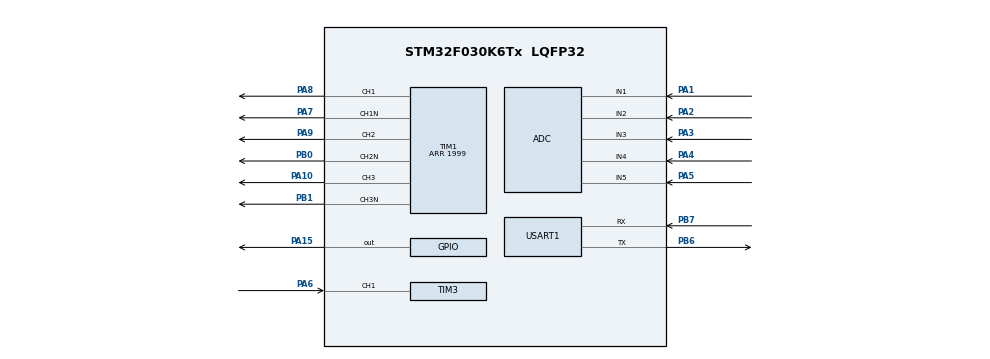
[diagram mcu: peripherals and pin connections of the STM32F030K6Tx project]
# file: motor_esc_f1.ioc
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ADC.ContinuousConvMode=ENABLE
ADC.DMAContinuousRequests=ENABLE
ADC.EOCSelection=ADC_EOC_SEQ_CONV
Dma.ADC.1.Direction=DMA_PERIPH_TO_MEMORY
Dma.ADC.1.Instance=DMA1_Channel1
Dma.ADC.1.MemDataAlignment=DMA_MDATAALIGN_HALFWORD
Dma.ADC.1.MemInc=DMA_MINC_ENABLE
Dma.ADC.1.Mode=DMA_NORMAL
Dma.ADC.1.PeriphDataAlignment=DMA_PDATAALIGN_HALFWORD
Dma.ADC.1.PeriphInc=DMA_PINC_DISABLE
Dma.ADC.1.Priority=DMA_PRIORITY_LOW
Dma.Request0=TIM3_CH1/TRIG
Dma.Request1=ADC
Dma.Request2=TIM1_CH1
Dma.Request3=TIM1_CH2
Dma.Request4=TIM1_CH3/UP
Dma.TIM1_CH1.2.Direction=DMA_PERIPH_TO_MEMORY
Dma.TIM1_CH1.2.Instance=DMA1_Channel2
Dma.TIM1_CH1.2.MemDataAlignment=DMA_MDATAALIGN_HALFWORD
Dma.TIM1_CH1.2.MemInc=DMA_MINC_ENABLE
Dma.TIM1_CH1.2.Mode=DMA_NORMAL
Dma.TIM1_CH1.2.PeriphDataAlignment=DMA_PDATAALIGN_HALFWORD
Dma.TIM1_CH1.2.PeriphInc=DMA_PINC_DISABLE
Dma.TIM1_CH1.2.Priority=DMA_PRIORITY_LOW
Dma.TIM1_CH2.3.Direction=DMA_PERIPH_TO_MEMORY
Dma.TIM1_CH2.3.Instance=DMA1_Channel3
Dma.TIM1_CH2.3.MemDataAlignment=DMA_MDATAALIGN_HALFWORD
Dma.TIM1_CH2.3.MemInc=DMA_MINC_ENABLE
Dma.TIM1_CH2.3.Mode=DMA_NORMAL
Dma.TIM1_CH2.3.PeriphDataAlignment=DMA_PDATAALIGN_HALFWORD
Dma.TIM1_CH2.3.PeriphInc=DMA_PINC_DISABLE
Dma.TIM1_CH2.3.Priority=DMA_PRIORITY_LOW
Dma.TIM1_CH3/UP.4.Direction=DMA_PERIPH_TO_MEMORY
Dma.TIM1_CH3/UP.4.Instance=DMA1_Channel5
Dma.TIM1_CH3/UP.4.MemDataAlignment=DMA_MDATAALIGN_HALFWORD
Dma.TIM1_CH3/UP.4.MemInc=DMA_MINC_ENABLE
Dma.TIM1_CH3/UP.4.Mode=DMA_NORMAL
Dma.TIM1_CH3/UP.4.PeriphDataAlignment=DMA_PDATAALIGN_HALFWORD
Dma.TIM1_CH3/UP.4.PeriphInc=DMA_PINC_DISABLE
Dma.TIM1_CH3/UP.4.Priority=DMA_PRIORITY_LOW
Dma.TIM3_CH1/TRIG.0.Direction=DMA_PERIPH_TO_MEMORY
Dma.TIM3_CH1/TRIG.0.Instance=DMA1_Channel4
Dma.TIM3_CH1/TRIG.0.MemDataAlignment=DMA_MDATAALIGN_HALFWORD
Dma.TIM3_CH1/TRIG.0.MemInc=DMA_MINC_ENABLE
Dma.TIM3_CH1/TRIG.0.Mode=DMA_NORMAL
Dma.TIM3_CH1/TRIG.0.PeriphDataAlignment=DMA_PDATAALIGN_HALFWORD
Dma.TIM3_CH1/TRIG.0.PeriphInc=DMA_PINC_DISABLE
Dma.TIM3_CH1/TRIG.0.Priority=DMA_PRIORITY_LOW
Mcu.Family=STM32F0
Mcu.Name=STM32F030K6Tx
Mcu.Package=LQFP32
NVIC.DMA1_Channel1_IRQn=true\:0\:0\:false\:false\:true\:false\:true\:true
NVIC.DMA1_Channel2_3_IRQn=true\:0\:0\:false\:false\:true\:false\:true\:true
NVIC.DMA1_Channel4_5_IRQn=true\:0\:0\:false\:false\:true\:false\:true\:true
NVIC.TIM14_IRQn=true\:0\:0\:false\:false\:true\:true\:true\:true
NVIC.TIM1_BRK_UP_TRG_COM_IRQn=true\:0\:0\:false\:false\:true\:true\:true\:true
NVIC.TIM3_IRQn=true\:0\:0\:false\:false\:true\:true\:true\:true
PA1.Mode=IN1
PA1.Signal=ADC_IN1
PA10.Signal=S_TIM1_CH3
PA13.Mode=Serial_Wire
PA13.Signal=SYS_SWDIO
PA14.Mode=Serial_Wire
PA14.Signal=SYS_SWCLK
PA15.Signal=GPIO_Output
PA2.Mode=IN2
PA2.Signal=ADC_IN2
PA3.Mode=IN3
PA3.Signal=ADC_IN3
PA4.Mode=IN4
PA4.Signal=ADC_IN4
PA5.Mode=IN5
PA5.Signal=ADC_IN5
PA6.Signal=S_TIM3_CH1
PA7.Mode=PWM Generation1 CH1 CH1N
PA7.Signal=TIM1_CH1N
PA8.Signal=S_TIM1_CH1
PA9.Signal=S_TIM1_CH2
PB0.Mode=PWM Generation2 CH2 CH2N
PB0.Signal=TIM1_CH2N
PB1.Mode=PWM Generation3 CH3 CH3N
PB1.Signal=TIM1_CH3N
PB6.Mode=Asynchronous
PB6.Signal=USART1_TX
PB7.Mode=Asynchronous
PB7.Signal=USART1_RX
ProjectManager.HeapSize=0x200
ProjectManager.StackSize=0x400
ProjectManager.TargetToolchain=STM32CubeIDE
RCC.AHBFreq_Value=48000000
RCC.APB1Freq_Value=48000000
RCC.APB1TimFreq_Value=48000000
RCC.HCLKFreq_Value=48000000
RCC.PLLMUL=RCC_PLL_MUL12
RCC.SYSCLKFreq_VALUE=48000000
RCC.SYSCLKSource=RCC_SYSCLKSOURCE_PLLCLK
SH.S_TIM1_CH1.0=TIM1_CH1,PWM Generation1 CH1 CH1N
SH.S_TIM1_CH2.0=TIM1_CH2,PWM Generation2 CH2 CH2N
SH.S_TIM1_CH3.0=TIM1_CH3,PWM Generation3 CH3 CH3N
SH.S_TIM3_CH1.0=TIM3_CH1,Input_Capture1_from_TI1
TIM1.Channel-PWM\ Generation1\ CH1\ CH1N=TIM_CHANNEL_1
TIM1.Channel-PWM\ Generation2\ CH2\ CH2N=TIM_CHANNEL_2
TIM1.Channel-PWM\ Generation3\ CH3\ CH3N=TIM_CHANNEL_3
TIM1.DeadTime=45
TIM1.OCIdleState_1=TIM_OCIDLESTATE_SET
TIM1.OCIdleState_2=TIM_OCIDLESTATE_SET
TIM1.OCIdleState_3=TIM_OCIDLESTATE_SET
TIM1.OCNIdleState_1=TIM_OCNIDLESTATE_RESET
TIM1.Period=1999
TIM1.Pulse-PWM\ Generation1\ CH1\ CH1N=1000
TIM1.Pulse-PWM\ Generation3\ CH3\ CH3N=1000
TIM1.TIM_MasterOutputTrigger=TIM_TRGO_ENABLE
TIM14.AutoReloadPreload=TIM_AUTORELOAD_PRELOAD_ENABLE
TIM14.Channel=TIM_CHANNEL_1
TIM14.Period=16000
TIM14.Prescaler=10
TIM16.AutoReloadPreload=TIM_AUTORELOAD_PRELOAD_ENABLE
TIM16.Prescaler=479
TIM17.AutoReloadPreload=TIM_AUTORELOAD_PRELOAD_ENABLE
TIM3.Channel-Input_Capture1_from_TI1=TIM_CHANNEL_1
TIM3.Prescaler=99
USART1.VirtualMode-Asynchronous=VM_ASYNC
VP_ADC_TempSens_Input.Mode=IN-TempSens
VP_TIM14_VS_ClockSourceINT.Mode=Enable_Timer
VP_TIM14_VS_no_output1.Mode=Output Compare1 No Output
VP_TIM16_VS_ClockSourceINT.Mode=Enable_Timer
VP_TIM17_VS_ClockSourceINT.Mode=Enable_Timer
VP_TIM1_VS_ClockSourceINT.Mode=Internal
board=custom

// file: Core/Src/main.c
/* USER CODE BEGIN Header */
/**
  ******************************************************************************
  * @file           : main.c
  * @brief          : Main program body
  ******************************************************************************
  * @attention
  *
  * Copyright (c) 2022 STMicroelectronics.
  * All rights reserved.
  *
  * This software is licensed under terms that can be found in the LICENSE file
  * in the root directory of this software component.
  * If no LICENSE file comes with this software, it is provided AS-IS.
  *
  ******************************************************************************
  */
/* USER CODE END Header */
#include "main.h"

void SystemClock_Config(void);
static void MX_GPIO_Init(void);
static void MX_DMA_Init(void);
static void MX_TIM1_Init(void);
static void MX_ADC_Init(void);
static void MX_TIM3_Init(void);
static void MX_TIM14_Init(void);
static void MX_USART1_UART_Init(void);
static void MX_TIM16_Init(void);
static void MX_TIM17_Init(void);

int main(void)
{

  /* MCU Configuration--------------------------------------------------------*/

  /* Reset of all peripherals, Initializes the Flash interface and the Systick. */
  LL_APB1_GRP2_EnableClock(LL_APB1_GRP2_PERIPH_SYSCFG);
  LL_APB1_GRP1_EnableClock(LL_APB1_GRP1_PERIPH_PWR);

  /* SysTick_IRQn interrupt configuration */
  NVIC_SetPriority(SysTick_IRQn, 3);

  /* Configure the system clock */
  SystemClock_Config();

  /* Initialize all configured peripherals */
  MX_GPIO_Init();
  MX_DMA_Init();
  MX_TIM1_Init();
  MX_ADC_Init();
  MX_TIM3_Init();
  MX_TIM14_Init();
  MX_USART1_UART_Init();
  MX_TIM16_Init();
  MX_TIM17_Init();
  /* USER CODE BEGIN 2 */
  LL_GPIO_SetOutputPin(GPIOA, LL_GPIO_PIN_15);
  /* USER CODE END 2 */

  /* Infinite loop */
  while (1)
  {

  }
}

void SystemClock_Config(void)
{
  LL_FLASH_SetLatency(LL_FLASH_LATENCY_1);
  while(LL_FLASH_GetLatency() != LL_FLASH_LATENCY_1)
  {
  }
  LL_RCC_HSI_Enable();

   /* Wait till HSI is ready */
  while(LL_RCC_HSI_IsReady() != 1)
  {

  }
  LL_RCC_HSI_SetCalibTrimming(16);
  LL_RCC_HSI14_Enable();

   /* Wait till HSI14 is ready */
  while(LL_RCC_HSI14_IsReady() != 1)
  {

  }
  LL_RCC_HSI14_SetCalibTrimming(16);
  LL_RCC_PLL_ConfigDomain_SYS(LL_RCC_PLLSOURCE_HSI_DIV_2, LL_RCC_PLL_MUL_12);
  LL_RCC_PLL_Enable();

   /* Wait till PLL is ready */
  while(LL_RCC_PLL_IsReady() != 1)
  {

  }
  LL_RCC_SetAHBPrescaler(LL_RCC_SYSCLK_DIV_1);
  LL_RCC_SetAPB1Prescaler(LL_RCC_APB1_DIV_1);
  LL_RCC_SetSysClkSource(LL_RCC_SYS_CLKSOURCE_PLL);

   /* Wait till System clock is ready */
  while(LL_RCC_GetSysClkSource() != LL_RCC_SYS_CLKSOURCE_STATUS_PLL)
  {

  }
  LL_Init1msTick(48000000);
  LL_SetSystemCoreClock(48000000);
  LL_RCC_HSI14_EnableADCControl();
  LL_RCC_SetUSARTClockSource(LL_RCC_USART1_CLKSOURCE_PCLK1);
}

static void MX_ADC_Init(void)
{

  LL_ADC_InitTypeDef ADC_InitStruct = {0};
  LL_ADC_REG_InitTypeDef ADC_REG_InitStruct = {0};

  LL_GPIO_InitTypeDef GPIO_InitStruct = {0};

  /* Peripheral clock enable */
  LL_APB1_GRP2_EnableClock(LL_APB1_GRP2_PERIPH_ADC1);

  LL_AHB1_GRP1_EnableClock(LL_AHB1_GRP1_PERIPH_GPIOA);
  /**ADC GPIO Configuration
  PA1   ------> ADC_IN1
  PA2   ------> ADC_IN2
  PA3   ------> ADC_IN3
  PA4   ------> ADC_IN4
  PA5   ------> ADC_IN5
  */
  GPIO_InitStruct.Pin = LL_GPIO_PIN_1;
  GPIO_InitStruct.Mode = LL_GPIO_MODE_ANALOG;
  GPIO_InitStruct.Pull = LL_GPIO_PULL_NO;
  LL_GPIO_Init(GPIOA, &GPIO_InitStruct);

  GPIO_InitStruct.Pin = LL_GPIO_PIN_2;
  GPIO_InitStruct.Mode = LL_GPIO_MODE_ANALOG;
  GPIO_InitStruct.Pull = LL_GPIO_PULL_NO;
  LL_GPIO_Init(GPIOA, &GPIO_InitStruct);

  GPIO_InitStruct.Pin = LL_GPIO_PIN_3;
  GPIO_InitStruct.Mode = LL_GPIO_MODE_ANALOG;
  GPIO_InitStruct.Pull = LL_GPIO_PULL_NO;
  LL_GPIO_Init(GPIOA, &GPIO_InitStruct);

  GPIO_InitStruct.Pin = LL_GPIO_PIN_4;
  GPIO_InitStruct.Mode = LL_GPIO_MODE_ANALOG;
  GPIO_InitStruct.Pull = LL_GPIO_PULL_NO;
  LL_GPIO_Init(GPIOA, &GPIO_InitStruct);

  GPIO_InitStruct.Pin = LL_GPIO_PIN_5;
  GPIO_InitStruct.Mode = LL_GPIO_MODE_ANALOG;
  GPIO_InitStruct.Pull = LL_GPIO_PULL_NO;
  LL_GPIO_Init(GPIOA, &GPIO_InitStruct);

  /* ADC DMA Init */

  /* ADC Init */
  LL_DMA_SetDataTransferDirection(DMA1, LL_DMA_CHANNEL_1, LL_DMA_DIRECTION_PERIPH_TO_MEMORY);

  LL_DMA_SetChannelPriorityLevel(DMA1, LL_DMA_CHANNEL_1, LL_DMA_PRIORITY_LOW);

  LL_DMA_SetMode(DMA1, LL_DMA_CHANNEL_1, LL_DMA_MODE_NORMAL);

  LL_DMA_SetPeriphIncMode(DMA1, LL_DMA_CHANNEL_1, LL_DMA_PERIPH_NOINCREMENT);

  LL_DMA_SetMemoryIncMode(DMA1, LL_DMA_CHANNEL_1, LL_DMA_MEMORY_INCREMENT);

  LL_DMA_SetPeriphSize(DMA1, LL_DMA_CHANNEL_1, LL_DMA_PDATAALIGN_HALFWORD);

  LL_DMA_SetMemorySize(DMA1, LL_DMA_CHANNEL_1, LL_DMA_MDATAALIGN_HALFWORD);

  /** Configure Regular Channel
  */
  LL_ADC_REG_SetSequencerChAdd(ADC1, LL_ADC_CHANNEL_1);

  /** Configure Regular Channel
  */
  LL_ADC_REG_SetSequencerChAdd(ADC1, LL_ADC_CHANNEL_2);

  /** Configure Regular Channel
  */
  LL_ADC_REG_SetSequencerChAdd(ADC1, LL_ADC_CHANNEL_3);

  /** Configure Regular Channel
  */
  LL_ADC_REG_SetSequencerChAdd(ADC1, LL_ADC_CHANNEL_4);

  /** Configure Regular Channel
  */
  LL_ADC_REG_SetSequencerChAdd(ADC1, LL_ADC_CHANNEL_5);

  /** Configure Regular Channel
  */
  LL_ADC_REG_SetSequencerChAdd(ADC1, LL_ADC_CHANNEL_TEMPSENSOR);

  /** Configure Internal Channel
  */
  LL_ADC_SetCommonPathInternalCh(__LL_ADC_COMMON_INSTANCE(ADC1), LL_ADC_PATH_INTERNAL_TEMPSENSOR);

  /** Configure the global features of the ADC (Clock, Resolution, Data Alignment and number of conversion)
  */
  ADC_InitStruct.Clock = LL_ADC_CLOCK_ASYNC;
  ADC_InitStruct.Resolution = LL_ADC_RESOLUTION_12B;
  ADC_InitStruct.DataAlignment = LL_ADC_DATA_ALIGN_RIGHT;
  ADC_InitStruct.LowPowerMode = LL_ADC_LP_MODE_NONE;
  LL_ADC_Init(ADC1, &ADC_InitStruct);
  ADC_REG_InitStruct.TriggerSource = LL_ADC_REG_TRIG_SOFTWARE;
  ADC_REG_InitStruct.SequencerDiscont = LL_ADC_REG_SEQ_DISCONT_DISABLE;
  ADC_REG_InitStruct.ContinuousMode = LL_ADC_REG_CONV_CONTINUOUS;
  ADC_REG_InitStruct.DMATransfer = LL_ADC_REG_DMA_TRANSFER_UNLIMITED;
  ADC_REG_InitStruct.Overrun = LL_ADC_REG_OVR_DATA_PRESERVED;
  LL_ADC_REG_Init(ADC1, &ADC_REG_InitStruct);
  LL_ADC_REG_SetSequencerScanDirection(ADC1, LL_ADC_REG_SEQ_SCAN_DIR_FORWARD);
  LL_ADC_SetSamplingTimeCommonChannels(ADC1, LL_ADC_SAMPLINGTIME_1CYCLE_5);

}

static void MX_TIM1_Init(void)
{

  LL_TIM_InitTypeDef TIM_InitStruct = {0};
  LL_TIM_OC_InitTypeDef TIM_OC_InitStruct = {0};
  LL_TIM_BDTR_InitTypeDef TIM_BDTRInitStruct = {0};

  LL_GPIO_InitTypeDef GPIO_InitStruct = {0};

  /* Peripheral clock enable */
  LL_APB1_GRP2_EnableClock(LL_APB1_GRP2_PERIPH_TIM1);

  /* TIM1 DMA Init */

  /* TIM1_CH1 Init */
  LL_DMA_SetDataTransferDirection(DMA1, LL_DMA_CHANNEL_2, LL_DMA_DIRECTION_PERIPH_TO_MEMORY);

  LL_DMA_SetChannelPriorityLevel(DMA1, LL_DMA_CHANNEL_2, LL_DMA_PRIORITY_LOW);

  LL_DMA_SetMode(DMA1, LL_DMA_CHANNEL_2, LL_DMA_MODE_NORMAL);

  LL_DMA_SetPeriphIncMode(DMA1, LL_DMA_CHANNEL_2, LL_DMA_PERIPH_NOINCREMENT);

  LL_DMA_SetMemoryIncMode(DMA1, LL_DMA_CHANNEL_2, LL_DMA_MEMORY_INCREMENT);

  LL_DMA_SetPeriphSize(DMA1, LL_DMA_CHANNEL_2, LL_DMA_PDATAALIGN_HALFWORD);

  LL_DMA_SetMemorySize(DMA1, LL_DMA_CHANNEL_2, LL_DMA_MDATAALIGN_HALFWORD);

  /* TIM1_CH2 Init */
  LL_DMA_SetDataTransferDirection(DMA1, LL_DMA_CHANNEL_3, LL_DMA_DIRECTION_PERIPH_TO_MEMORY);

  LL_DMA_SetChannelPriorityLevel(DMA1, LL_DMA_CHANNEL_3, LL_DMA_PRIORITY_LOW);

  LL_DMA_SetMode(DMA1, LL_DMA_CHANNEL_3, LL_DMA_MODE_NORMAL);

  LL_DMA_SetPeriphIncMode(DMA1, LL_DMA_CHANNEL_3, LL_DMA_PERIPH_NOINCREMENT);

  LL_DMA_SetMemoryIncMode(DMA1, LL_DMA_CHANNEL_3, LL_DMA_MEMORY_INCREMENT);

  LL_DMA_SetPeriphSize(DMA1, LL_DMA_CHANNEL_3, LL_DMA_PDATAALIGN_HALFWORD);

  LL_DMA_SetMemorySize(DMA1, LL_DMA_CHANNEL_3, LL_DMA_MDATAALIGN_HALFWORD);

  /* TIM1_CH3_UP Init */
  LL_DMA_SetDataTransferDirection(DMA1, LL_DMA_CHANNEL_5, LL_DMA_DIRECTION_PERIPH_TO_MEMORY);

  LL_DMA_SetChannelPriorityLevel(DMA1, LL_DMA_CHANNEL_5, LL_DMA_PRIORITY_LOW);

  LL_DMA_SetMode(DMA1, LL_DMA_CHANNEL_5, LL_DMA_MODE_NORMAL);

  LL_DMA_SetPeriphIncMode(DMA1, LL_DMA_CHANNEL_5, LL_DMA_PERIPH_NOINCREMENT);

  LL_DMA_SetMemoryIncMode(DMA1, LL_DMA_CHANNEL_5, LL_DMA_MEMORY_INCREMENT);

  LL_DMA_SetPeriphSize(DMA1, LL_DMA_CHANNEL_5, LL_DMA_PDATAALIGN_HALFWORD);

  LL_DMA_SetMemorySize(DMA1, LL_DMA_CHANNEL_5, LL_DMA_MDATAALIGN_HALFWORD);

  /* TIM1 interrupt Init */
  NVIC_SetPriority(TIM1_BRK_UP_TRG_COM_IRQn, 0);
  NVIC_EnableIRQ(TIM1_BRK_UP_TRG_COM_IRQn);

  TIM_InitStruct.Prescaler = 0;
  TIM_InitStruct.CounterMode = LL_TIM_COUNTERMODE_UP;
  TIM_InitStruct.Autoreload = 1999;
  TIM_InitStruct.ClockDivision = LL_TIM_CLOCKDIVISION_DIV1;
  TIM_InitStruct.RepetitionCounter = 0;
  LL_TIM_Init(TIM1, &TIM_InitStruct);
  LL_TIM_DisableARRPreload(TIM1);
  LL_TIM_SetClockSource(TIM1, LL_TIM_CLOCKSOURCE_INTERNAL);
  LL_TIM_OC_EnablePreload(TIM1, LL_TIM_CHANNEL_CH1);
  TIM_OC_InitStruct.OCMode = LL_TIM_OCMODE_PWM1;
  TIM_OC_InitStruct.OCState = LL_TIM_OCSTATE_DISABLE;
  TIM_OC_InitStruct.OCNState = LL_TIM_OCSTATE_DISABLE;
  TIM_OC_InitStruct.CompareValue = 1000;
  TIM_OC_InitStruct.OCPolarity = LL_TIM_OCPOLARITY_HIGH;
  TIM_OC_InitStruct.OCNPolarity = LL_TIM_OCPOLARITY_HIGH;
  TIM_OC_InitStruct.OCIdleState = LL_TIM_OCIDLESTATE_HIGH;
  TIM_OC_InitStruct.OCNIdleState = LL_TIM_OCIDLESTATE_LOW;
  LL_TIM_OC_Init(TIM1, LL_TIM_CHANNEL_CH1, &TIM_OC_InitStruct);
  LL_TIM_OC_DisableFast(TIM1, LL_TIM_CHANNEL_CH1);
  LL_TIM_OC_EnablePreload(TIM1, LL_TIM_CHANNEL_CH2);
  TIM_OC_InitStruct.CompareValue = 0;
  LL_TIM_OC_Init(TIM1, LL_TIM_CHANNEL_CH2, &TIM_OC_InitStruct);
  LL_TIM_OC_DisableFast(TIM1, LL_TIM_CHANNEL_CH2);
  LL_TIM_OC_EnablePreload(TIM1, LL_TIM_CHANNEL_CH3);
  TIM_OC_InitStruct.CompareValue = 1000;
  LL_TIM_OC_Init(TIM1, LL_TIM_CHANNEL_CH3, &TIM_OC_InitStruct);
  LL_TIM_OC_DisableFast(TIM1, LL_TIM_CHANNEL_CH3);
  LL_TIM_SetTriggerOutput(TIM1, LL_TIM_TRGO_ENABLE);
  LL_TIM_DisableMasterSlaveMode(TIM1);
  TIM_BDTRInitStruct.OSSRState = LL_TIM_OSSR_DISABLE;
  TIM_BDTRInitStruct.OSSIState = LL_TIM_OSSI_DISABLE;
  TIM_BDTRInitStruct.LockLevel = LL_TIM_LOCKLEVEL_OFF;
  TIM_BDTRInitStruct.DeadTime = 45;
  TIM_BDTRInitStruct.BreakState = LL_TIM_BREAK_DISABLE;
  TIM_BDTRInitStruct.BreakPolarity = LL_TIM_BREAK_POLARITY_HIGH;
  TIM_BDTRInitStruct.AutomaticOutput = LL_TIM_AUTOMATICOUTPUT_DISABLE;
  LL_TIM_BDTR_Init(TIM1, &TIM_BDTRInitStruct);
  LL_AHB1_GRP1_EnableClock(LL_AHB1_GRP1_PERIPH_GPIOA);
  LL_AHB1_GRP1_EnableClock(LL_AHB1_GRP1_PERIPH_GPIOB);
  /**TIM1 GPIO Configuration
  PA7   ------> TIM1_CH1N
  PB0   ------> TIM1_CH2N
  PB1   ------> TIM1_CH3N
  PA8   ------> TIM1_CH1
  PA9   ------> TIM1_CH2
  PA10   ------> TIM1_CH3
  */
  GPIO_InitStruct.Pin = LL_GPIO_PIN_7;
  GPIO_InitStruct.Mode = LL_GPIO_MODE_ALTERNATE;
  GPIO_InitStruct.Speed = LL_GPIO_SPEED_FREQ_LOW;
  GPIO_InitStruct.OutputType = LL_GPIO_OUTPUT_PUSHPULL;
  GPIO_InitStruct.Pull = LL_GPIO_PULL_NO;
  GPIO_InitStruct.Alternate = LL_GPIO_AF_2;
  LL_GPIO_Init(GPIOA, &GPIO_InitStruct);

  GPIO_InitStruct.Pin = LL_GPIO_PIN_0;
  GPIO_InitStruct.Mode = LL_GPIO_MODE_ALTERNATE;
  GPIO_InitStruct.Speed = LL_GPIO_SPEED_FREQ_LOW;
  GPIO_InitStruct.OutputType = LL_GPIO_OUTPUT_PUSHPULL;
  GPIO_InitStruct.Pull = LL_GPIO_PULL_NO;
  GPIO_InitStruct.Alternate = LL_GPIO_AF_2;
  LL_GPIO_Init(GPIOB, &GPIO_InitStruct);

  GPIO_InitStruct.Pin = LL_GPIO_PIN_1;
  GPIO_InitStruct.Mode = LL_GPIO_MODE_ALTERNATE;
  GPIO_InitStruct.Speed = LL_GPIO_SPEED_FREQ_LOW;
  GPIO_InitStruct.OutputType = LL_GPIO_OUTPUT_PUSHPULL;
  GPIO_InitStruct.Pull = LL_GPIO_PULL_NO;
  GPIO_InitStruct.Alternate = LL_GPIO_AF_2;
  LL_GPIO_Init(GPIOB, &GPIO_InitStruct);

  GPIO_InitStruct.Pin = LL_GPIO_PIN_8;
  GPIO_InitStruct.Mode = LL_GPIO_MODE_ALTERNATE;
  GPIO_InitStruct.Speed = LL_GPIO_SPEED_FREQ_LOW;
  GPIO_InitStruct.OutputType = LL_GPIO_OUTPUT_PUSHPULL;
  GPIO_InitStruct.Pull = LL_GPIO_PULL_NO;
  GPIO_InitStruct.Alternate = LL_GPIO_AF_2;
  LL_GPIO_Init(GPIOA, &GPIO_InitStruct);

  GPIO_InitStruct.Pin = LL_GPIO_PIN_9;
  GPIO_InitStruct.Mode = LL_GPIO_MODE_ALTERNATE;
  GPIO_InitStruct.Speed = LL_GPIO_SPEED_FREQ_LOW;
  GPIO_InitStruct.OutputType = LL_GPIO_OUTPUT_PUSHPULL;
  GPIO_InitStruct.Pull = LL_GPIO_PULL_NO;
  GPIO_InitStruct.Alternate = LL_GPIO_AF_2;
  LL_GPIO_Init(GPIOA, &GPIO_InitStruct);

  GPIO_InitStruct.Pin = LL_GPIO_PIN_10;
  GPIO_InitStruct.Mode = LL_GPIO_MODE_ALTERNATE;
  GPIO_InitStruct.Speed = LL_GPIO_SPEED_FREQ_LOW;
  GPIO_InitStruct.OutputType = LL_GPIO_OUTPUT_PUSHPULL;
  GPIO_InitStruct.Pull = LL_GPIO_PULL_NO;
  GPIO_InitStruct.Alternate = LL_GPIO_AF_2;
  LL_GPIO_Init(GPIOA, &GPIO_InitStruct);

}

static void MX_TIM3_Init(void)
{

  LL_TIM_InitTypeDef TIM_InitStruct = {0};

  LL_GPIO_InitTypeDef GPIO_InitStruct = {0};

  /* Peripheral clock enable */
  LL_APB1_GRP1_EnableClock(LL_APB1_GRP1_PERIPH_TIM3);

  LL_AHB1_GRP1_EnableClock(LL_AHB1_GRP1_PERIPH_GPIOA);
  /**TIM3 GPIO Configuration
  PA6   ------> TIM3_CH1
  */
  GPIO_InitStruct.Pin = LL_GPIO_PIN_6;
  GPIO_InitStruct.Mode = LL_GPIO_MODE_ALTERNATE;
  GPIO_InitStruct.Speed = LL_GPIO_SPEED_FREQ_LOW;
  GPIO_InitStruct.OutputType = LL_GPIO_OUTPUT_PUSHPULL;
  GPIO_InitStruct.Pull = LL_GPIO_PULL_NO;
  GPIO_InitStruct.Alternate = LL_GPIO_AF_1;
  LL_GPIO_Init(GPIOA, &GPIO_InitStruct);

  /* TIM3 DMA Init */

  /* TIM3_CH1_TRIG Init */
  LL_DMA_SetDataTransferDirection(DMA1, LL_DMA_CHANNEL_4, LL_DMA_DIRECTION_PERIPH_TO_MEMORY);

  LL_DMA_SetChannelPriorityLevel(DMA1, LL_DMA_CHANNEL_4, LL_DMA_PRIORITY_LOW);

  LL_DMA_SetMode(DMA1, LL_DMA_CHANNEL_4, LL_DMA_MODE_NORMAL);

  LL_DMA_SetPeriphIncMode(DMA1, LL_DMA_CHANNEL_4, LL_DMA_PERIPH_NOINCREMENT);

  LL_DMA_SetMemoryIncMode(DMA1, LL_DMA_CHANNEL_4, LL_DMA_MEMORY_INCREMENT);

  LL_DMA_SetPeriphSize(DMA1, LL_DMA_CHANNEL_4, LL_DMA_PDATAALIGN_HALFWORD);

  LL_DMA_SetMemorySize(DMA1, LL_DMA_CHANNEL_4, LL_DMA_MDATAALIGN_HALFWORD);

  /* TIM3 interrupt Init */
  NVIC_SetPriority(TIM3_IRQn, 0);
  NVIC_EnableIRQ(TIM3_IRQn);

  TIM_InitStruct.Prescaler = 99;
  TIM_InitStruct.CounterMode = LL_TIM_COUNTERMODE_UP;
  TIM_InitStruct.Autoreload = 65535;
  TIM_InitStruct.ClockDivision = LL_TIM_CLOCKDIVISION_DIV1;
  LL_TIM_Init(TIM3, &TIM_InitStruct);
  LL_TIM_DisableARRPreload(TIM3);
  LL_TIM_SetTriggerOutput(TIM3, LL_TIM_TRGO_RESET);
  LL_TIM_DisableMasterSlaveMode(TIM3);
  LL_TIM_IC_SetActiveInput(TIM3, LL_TIM_CHANNEL_CH1, LL_TIM_ACTIVEINPUT_DIRECTTI);
  LL_TIM_IC_SetPrescaler(TIM3, LL_TIM_CHANNEL_CH1, LL_TIM_ICPSC_DIV1);
  LL_TIM_IC_SetFilter(TIM3, LL_TIM_CHANNEL_CH1, LL_TIM_IC_FILTER_FDIV1);
  LL_TIM_IC_SetPolarity(TIM3, LL_TIM_CHANNEL_CH1, LL_TIM_IC_POLARITY_RISING);

}

static void MX_TIM14_Init(void)
{

  LL_TIM_InitTypeDef TIM_InitStruct = {0};
  LL_TIM_OC_InitTypeDef TIM_OC_InitStruct = {0};

  /* Peripheral clock enable */
  LL_APB1_GRP1_EnableClock(LL_APB1_GRP1_PERIPH_TIM14);

  /* TIM14 interrupt Init */
  NVIC_SetPriority(TIM14_IRQn, 0);
  NVIC_EnableIRQ(TIM14_IRQn);

  TIM_InitStruct.Prescaler = 10;
  TIM_InitStruct.CounterMode = LL_TIM_COUNTERMODE_UP;
  TIM_InitStruct.Autoreload = 16000;
  TIM_InitStruct.ClockDivision = LL_TIM_CLOCKDIVISION_DIV1;
  LL_TIM_Init(TIM14, &TIM_InitStruct);
  LL_TIM_EnableARRPreload(TIM14);
  TIM_OC_InitStruct.OCMode = LL_TIM_OCMODE_FROZEN;
  TIM_OC_InitStruct.OCState = LL_TIM_OCSTATE_DISABLE;
  TIM_OC_InitStruct.OCNState = LL_TIM_OCSTATE_DISABLE;
  TIM_OC_InitStruct.CompareValue = 0;
  TIM_OC_InitStruct.OCPolarity = LL_TIM_OCPOLARITY_HIGH;
  LL_TIM_OC_Init(TIM14, LL_TIM_CHANNEL_CH1, &TIM_OC_InitStruct);
  LL_TIM_OC_DisableFast(TIM14, LL_TIM_CHANNEL_CH1);

}

static void MX_TIM16_Init(void)
{

  LL_TIM_InitTypeDef TIM_InitStruct = {0};

  /* Peripheral clock enable */
  LL_APB1_GRP2_EnableClock(LL_APB1_GRP2_PERIPH_TIM16);

  TIM_InitStruct.Prescaler = 479;
  TIM_InitStruct.CounterMode = LL_TIM_COUNTERMODE_UP;
  TIM_InitStruct.Autoreload = 65535;
  TIM_InitStruct.ClockDivision = LL_TIM_CLOCKDIVISION_DIV1;
  TIM_InitStruct.RepetitionCounter = 0;
  LL_TIM_Init(TIM16, &TIM_InitStruct);
  LL_TIM_EnableARRPreload(TIM16);

}

static void MX_TIM17_Init(void)
{

  LL_TIM_InitTypeDef TIM_InitStruct = {0};

  /* Peripheral clock enable */
  LL_APB1_GRP2_EnableClock(LL_APB1_GRP2_PERIPH_TIM17);

  TIM_InitStruct.Prescaler = 0;
  TIM_InitStruct.CounterMode = LL_TIM_COUNTERMODE_UP;
  TIM_InitStruct.Autoreload = 65535;
  TIM_InitStruct.ClockDivision = LL_TIM_CLOCKDIVISION_DIV1;
  TIM_InitStruct.RepetitionCounter = 0;
  LL_TIM_Init(TIM17, &TIM_InitStruct);
  LL_TIM_EnableARRPreload(TIM17);

}

static void MX_USART1_UART_Init(void)
{

  LL_USART_InitTypeDef USART_InitStruct = {0};

  LL_GPIO_InitTypeDef GPIO_InitStruct = {0};

  /* Peripheral clock enable */
  LL_APB1_GRP2_EnableClock(LL_APB1_GRP2_PERIPH_USART1);

  LL_AHB1_GRP1_EnableClock(LL_AHB1_GRP1_PERIPH_GPIOB);
  /**USART1 GPIO Configuration
  PB6   ------> USART1_TX
  PB7   ------> USART1_RX
  */
  GPIO_InitStruct.Pin = LL_GPIO_PIN_6;
  GPIO_InitStruct.Mode = LL_GPIO_MODE_ALTERNATE;
  GPIO_InitStruct.Speed = LL_GPIO_SPEED_FREQ_HIGH;
  GPIO_InitStruct.OutputType = LL_GPIO_OUTPUT_PUSHPULL;
  GPIO_InitStruct.Pull = LL_GPIO_PULL_NO;
  GPIO_InitStruct.Alternate = LL_GPIO_AF_0;
  LL_GPIO_Init(GPIOB, &GPIO_InitStruct);

  GPIO_InitStruct.Pin = LL_GPIO_PIN_7;
  GPIO_InitStruct.Mode = LL_GPIO_MODE_ALTERNATE;
  GPIO_InitStruct.Speed = LL_GPIO_SPEED_FREQ_HIGH;
  GPIO_InitStruct.OutputType = LL_GPIO_OUTPUT_PUSHPULL;
  GPIO_InitStruct.Pull = LL_GPIO_PULL_NO;
  GPIO_InitStruct.Alternate = LL_GPIO_AF_0;
  LL_GPIO_Init(GPIOB, &GPIO_InitStruct);

  USART_InitStruct.BaudRate = 38400;
  USART_InitStruct.DataWidth = LL_USART_DATAWIDTH_8B;
  USART_InitStruct.StopBits = LL_USART_STOPBITS_1;
  USART_InitStruct.Parity = LL_USART_PARITY_NONE;
  USART_InitStruct.TransferDirection = LL_USART_DIRECTION_TX_RX;
  USART_InitStruct.HardwareFlowControl = LL_USART_HWCONTROL_NONE;
  USART_InitStruct.OverSampling = LL_USART_OVERSAMPLING_16;
  LL_USART_Init(USART1, &USART_InitStruct);
  LL_USART_DisableIT_CTS(USART1);
  LL_USART_ConfigAsyncMode(USART1);
  LL_USART_Enable(USART1);

}

static void MX_DMA_Init(void)
{

  /* Init with LL driver */
  /* DMA controller clock enable */
  LL_AHB1_GRP1_EnableClock(LL_AHB1_GRP1_PERIPH_DMA1);

  /* DMA interrupt init */
  /* DMA1_Channel1_IRQn interrupt configuration */
  NVIC_SetPriority(DMA1_Channel1_IRQn, 0);
  NVIC_EnableIRQ(DMA1_Channel1_IRQn);
  /* DMA1_Channel2_3_IRQn interrupt configuration */
  NVIC_SetPriority(DMA1_Channel2_3_IRQn, 0);
  NVIC_EnableIRQ(DMA1_Channel2_3_IRQn);
  /* DMA1_Channel4_5_IRQn interrupt configuration */
  NVIC_SetPriority(DMA1_Channel4_5_IRQn, 0);
  NVIC_EnableIRQ(DMA1_Channel4_5_IRQn);

}

static void MX_GPIO_Init(void)
{
  LL_GPIO_InitTypeDef GPIO_InitStruct = {0};

  /* GPIO Ports Clock Enable */
  LL_AHB1_GRP1_EnableClock(LL_AHB1_GRP1_PERIPH_GPIOA);
  LL_AHB1_GRP1_EnableClock(LL_AHB1_GRP1_PERIPH_GPIOB);

  /**/
  LL_GPIO_ResetOutputPin(GPIOA, LL_GPIO_PIN_15);

  /**/
  GPIO_InitStruct.Pin = LL_GPIO_PIN_15;
  GPIO_InitStruct.Mode = LL_GPIO_MODE_OUTPUT;
  GPIO_InitStruct.Speed = LL_GPIO_SPEED_FREQ_LOW;
  GPIO_InitStruct.OutputType = LL_GPIO_OUTPUT_PUSHPULL;
  GPIO_InitStruct.Pull = LL_GPIO_PULL_NO;
  LL_GPIO_Init(GPIOA, &GPIO_InitStruct);

}

void Error_Handler(void)
{
  __disable_irq();
  while (1)
  {
  }
}
